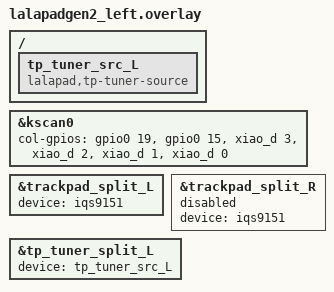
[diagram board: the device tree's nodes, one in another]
#include "lalapadgen2.dtsi"

&kscan0 {
    col-gpios
        = <&gpio0 19 GPIO_ACTIVE_HIGH>
        , <&gpio0 15 GPIO_ACTIVE_HIGH>
        , <&xiao_d 3 GPIO_ACTIVE_HIGH>
        , <&xiao_d 2 GPIO_ACTIVE_HIGH>
        , <&xiao_d 1 GPIO_ACTIVE_HIGH>
        , <&xiao_d 0 GPIO_ACTIVE_HIGH>
        ;
};

&trackpad_split_L {
    status = "okay";
    device = <&iqs9151>;
};
&trackpad_split_R {
    status = "disabled";
    device = <&iqs9151>;
};

// tp-tuner: peripheral 側の zmk,input-split は okay かつ device 必須なので、
// 何も report しない空デバイスを与える(送信は tp_tuner_peripheral.c が直接行う)
/ {
    tp_tuner_src_L: tp_tuner_src_L {
        compatible = "lalapad,tp-tuner-source";
    };
};

&tp_tuner_split_L {
    status = "okay";
    device = <&tp_tuner_src_L>;
};
